VERSION ""

NS_ :

BS_:

BU_: XXX

BO_ 1376 NEW_MSG_1: 8 XXX

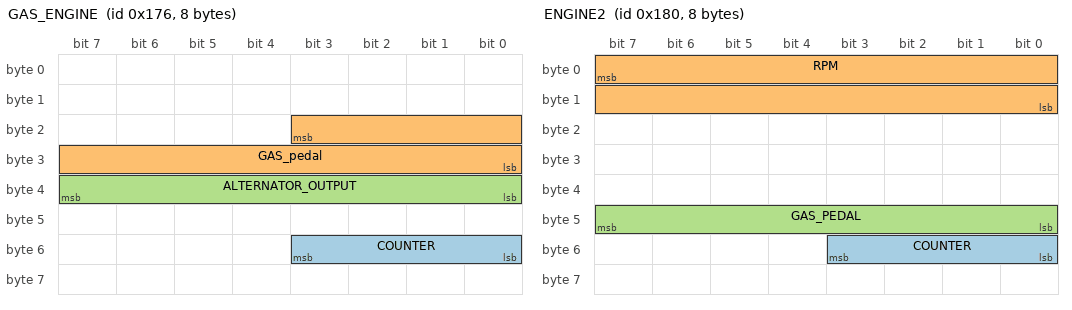
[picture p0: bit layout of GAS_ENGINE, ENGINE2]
BO_ 374 GAS_ENGINE: 8 XXX
 SG_ COUNTER : 51|4@0+ (1,0) [0|65535] "" XXX
 SG_ GAS_pedal : 19|12@0+ (0.0244140625,0) [0|4096] "percent" XXX
 SG_ ALTERNATOR_OUTPUT : 39|8@0+ (1,0) [0|65535] "" XXX

BO_ 421 NEW_MSG_2: 8 XXX
 SG_ COUNTER : 7|4@0+ (1,0) [0|15] "" XXX
 SG_ NEW_SIGNAL_1 : 23|8@0+ (1,0) [0|255] "" XXX

BO_ 1408 RPM: 8 XXX
 SG_ RPM : 7|16@0+ (1.5,0) [0|65535] "" XXX

BO_ 384 ENGINE2: 8 XXX
 SG_ COUNTER : 48|4@1+ (1,0) [0|15] "" XXX
 SG_ RPM : 7|16@0+ (0.1,0) [0|65535] "" XXX
 SG_ GAS_PEDAL : 47|8@0+ (0.392156862745098,0) [0|255] "" XXX

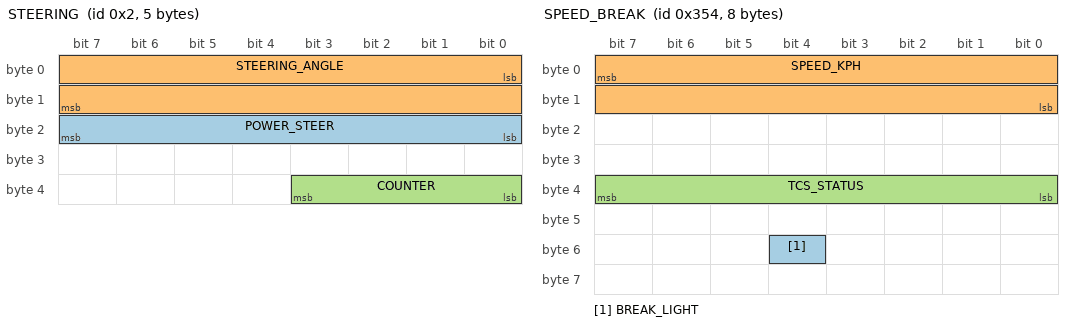
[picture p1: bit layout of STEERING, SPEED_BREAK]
BO_ 2 STEERING: 5 XXX
 SG_ POWER_STEER : 23|8@0+ (1,0) [0|255] "" XXX
 SG_ STEERING_ANGLE : 0|16@1- (1,0) [0|65535] "" XXX
 SG_ COUNTER : 35|4@0+ (1,0) [0|255] "" XXX

BO_ 352 NEW_MSG_5: 8 XXX
 SG_ NEW_SIGNAL_1 : 15|16@0- (1,0) [0|255] "" XXX

BO_ 505 ENG_RPM: 8 XXX
 SG_ RPM : 23|16@0+ (0.1,0) [0|65535] "rpm" XXX

BO_ 640 SPEED: 8 XXX
 SG_ SPEED_KPH : 39|16@0+ (0.01,0) [0|65535] "" XXX

BO_ 852 SPEED_BREAK: 8 XXX
 SG_ BREAK_LIGHT : 52|1@0+ (1,0) [0|3] "" XXX
 SG_ SPEED_KPH : 7|16@0+ (0.01,0) [0|65535] "kph" XXX
 SG_ TCS_STATUS : 39|8@0+ (1,0) [0|255] "" XXX

BO_ 853 SPEED2: 8 XXX
 SG_ SPEED_MPH : 7|16@0+ (0.00621371,0) [0|65535] "mph" XXX

BO_ 861 WIPERS: 8 XXX
 SG_ WIPER_USE : 23|4@0+ (1,0) [0|15] "" XXX
 SG_ MOVING_STATE : 39|4@0+ (1,0) [0|15] "" XXX

BO_ 1057 GEARS: 8 XXX
 SG_ LOW_GEAR : 4|1@1+ (1,0) [0|3] "" XXX
 SG_ DRIVE_GEAR : 5|1@0+ (1,0) [0|255] "" XXX

BO_ 1361 TEMP: 8 XXX
 SG_ TEMP : 7|8@0+ (1,0) [0|255] "" XXX

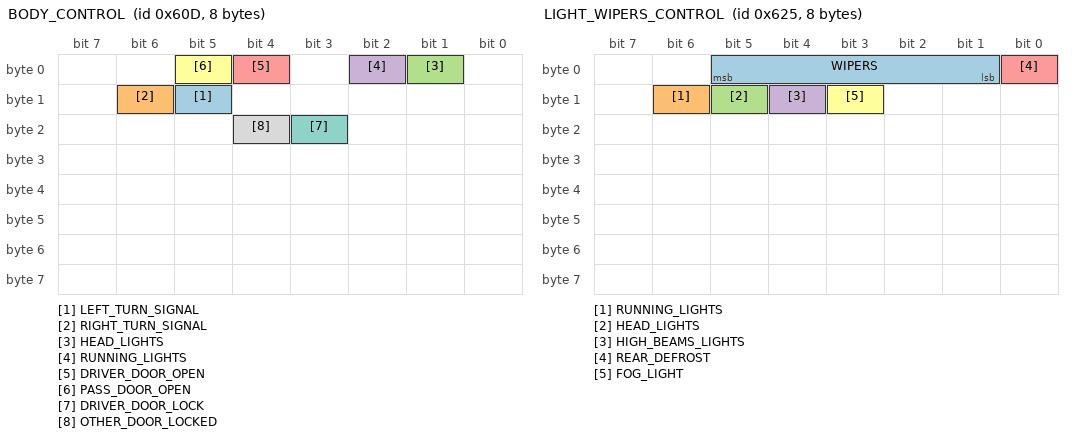
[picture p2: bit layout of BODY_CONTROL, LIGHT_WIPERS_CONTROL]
BO_ 1549 BODY_CONTROL: 8 XXX
 SG_ LEFT_TURN_SIGNAL : 13|1@0+ (1,0) [0|3] "" XXX
 SG_ RIGHT_TURN_SIGNAL : 14|1@0+ (1,0) [0|3] "" XXX
 SG_ HEAD_LIGHTS : 1|1@1+ (1,0) [0|3] "" XXX
 SG_ RUNNING_LIGHTS : 2|1@0+ (1,0) [0|3] "" XXX
 SG_ DRIVER_DOOR_OPEN : 4|1@0+ (1,0) [0|3] "" XXX
 SG_ PASS_DOOR_OPEN : 5|1@0+ (1,0) [0|3] "" XXX
 SG_ DRIVER_DOOR_LOCK : 19|1@1+ (1,0) [0|3] "" XXX
 SG_ OTHER_DOOR_LOCKED : 20|1@0+ (1,0) [0|3] "" XXX

BO_ 1573 LIGHT_WIPERS_CONTROL: 8 XXX
 SG_ WIPERS : 1|5@1+ (1,0) [0|31] "" XXX
 SG_ RUNNING_LIGHTS : 14|1@0+ (1,0) [0|3] "" XXX
 SG_ HEAD_LIGHTS : 13|1@0+ (1,0) [0|3] "" XXX
 SG_ HIGH_BEAMS_LIGHTS : 12|1@0+ (1,0) [0|3] "" XXX
 SG_ REAR_DEFROST : 0|1@0+ (1,0) [0|3] "" XXX
 SG_ FOG_LIGHT : 11|1@1+ (1,0) [0|3] "" XXX

BO_ 1477 PARKING_BREAK: 8 XXX
 SG_ PARKING_BREAK : 1|1@1+ (1,0) [0|3] "" XXX
 SG_ DISTANCE : 31|8@0+ (1,0) [0|255] "" XXX

BO_ 672 STEERING_MODULE: 8 XXX
 SG_ STEERING : 15|16@0+ (1,0) [0|255] "" XXX
 SG_ STEERING_ANGLE : 39|8@0- (1,0) [0|65535] "" XXX

CM_ SG_ 374 GAS_pedal "% of presee";
CM_ SG_ 374 ALTERNATOR_OUTPUT "?";
CM_ SG_ 640 SPEED_KPH "kmh";
CM_ SG_ 1057 DRIVE_GEAR "possible gear selection";
